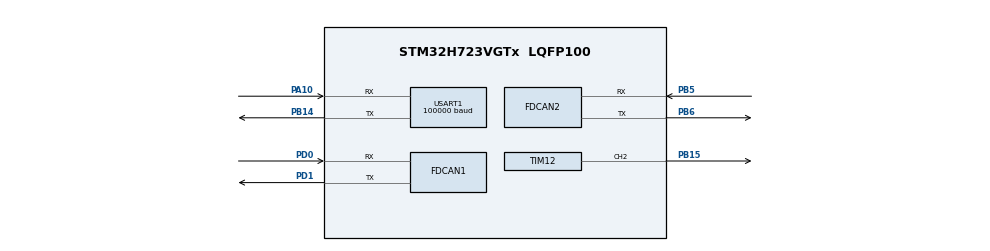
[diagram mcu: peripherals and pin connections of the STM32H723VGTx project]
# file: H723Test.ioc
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CORTEX_M7.default_mode_Activation=0
FDCAN1.AutoRetransmission=ENABLE
FDCAN1.CalculateBaudRateNominal=1000000
FDCAN1.CalculateTimeBitNominal=1000
FDCAN1.CalculateTimeQuantumNominal=12.5
FDCAN1.DataSyncJumpWidth=1
FDCAN1.DataTimeSeg1=1
FDCAN1.DataTimeSeg2=1
FDCAN1.ExtFiltersNbr=0
FDCAN1.FrameFormat=FDCAN_FRAME_CLASSIC
FDCAN1.NominalPrescaler=1
FDCAN1.NominalSyncJumpWidth=20
FDCAN1.NominalTimeSeg1=59
FDCAN1.NominalTimeSeg2=20
FDCAN1.ProtocolException=ENABLE
FDCAN1.RxBuffersNbr=0
FDCAN1.RxFifo0ElmtsNbr=10
FDCAN1.RxFifo1ElmtsNbr=0
FDCAN1.StdFiltersNbr=4
FDCAN1.TxBuffersNbr=0
FDCAN1.TxEventsNbr=0
FDCAN1.TxFifoQueueElmtsNbr=10
FDCAN2.AutoRetransmission=ENABLE
FDCAN2.CalculateBaudRateNominal=1000000
FDCAN2.CalculateTimeBitNominal=1000
FDCAN2.CalculateTimeQuantumNominal=12.5
FDCAN2.NominalPrescaler=1
FDCAN2.NominalSyncJumpWidth=20
FDCAN2.NominalTimeSeg1=59
FDCAN2.NominalTimeSeg2=20
FDCAN2.RxFifo0ElmtsNbr=10
FDCAN2.StdFiltersNbr=4
FDCAN2.TxFifoQueueElmtsNbr=10
FREERTOS.Tasks01=defaultTask,0,128,StartDefaultTask,Default,NULL,Dynamic,NULL,NULL
FREERTOS.configENABLE_FPU=1
Mcu.Family=STM32H7
Mcu.Name=STM32H723VGTx
Mcu.Package=LQFP100
NVIC.FDCAN1_IT0_IRQn=true\:5\:0\:false\:false\:true\:true\:true\:true\:true
NVIC.FDCAN2_IT0_IRQn=true\:5\:0\:false\:false\:true\:true\:true\:true\:true
NVIC.PriorityGroup=NVIC_PRIORITYGROUP_4
NVIC.TIM1_UP_IRQn=true\:15\:0\:false\:false\:true\:false\:false\:true\:true
NVIC.TimeBase=TIM1_UP_IRQn
NVIC.TimeBaseIP=TIM1
PA10.Mode=Asynchronous
PA10.Signal=USART1_RX
PA13(JTMS/SWDIO).Mode=Serial_Wire
PA13(JTMS/SWDIO).Signal=DEBUG_JTMS-SWDIO
PA14(JTCK/SWCLK).Mode=Serial_Wire
PA14(JTCK/SWCLK).Signal=DEBUG_JTCK-SWCLK
PB14.Mode=Asynchronous
PB14.Signal=USART1_TX
PB15.Signal=S_TIM12_CH2
PB5.Mode=FDCAN_Activate
PB5.Signal=FDCAN2_RX
PB6.Mode=FDCAN_Activate
PB6.Signal=FDCAN2_TX
PD0.Mode=FDCAN_Activate
PD0.Signal=FDCAN1_RX
PD1.Mode=FDCAN_Activate
PD1.Signal=FDCAN1_TX
PH0-OSC_IN.Mode=HSE-External-Oscillator
PH0-OSC_IN.Signal=RCC_OSC_IN
PH1-OSC_OUT.Mode=HSE-External-Oscillator
PH1-OSC_OUT.Signal=RCC_OSC_OUT
ProjectManager.HeapSize=0x200
ProjectManager.StackSize=0x400
ProjectManager.TargetToolchain=CMake
RCC.ADCFreq_Value=48375000
RCC.APB1Freq_Value=120000000
RCC.APB2Freq_Value=120000000
RCC.APB3Freq_Value=120000000
RCC.APB4Freq_Value=120000000
RCC.CortexFreq_Value=480000000
RCC.D1PPRE=RCC_APB3_DIV2
RCC.D2PPRE1=RCC_APB1_DIV2
RCC.D2PPRE2=RCC_APB2_DIV2
RCC.D3PPRE=RCC_APB4_DIV2
RCC.DIVM1=2
RCC.DIVN1=40
RCC.DIVP1=1
RCC.DIVQ1=6
RCC.HCLKFreq_Value=240000000
RCC.HPRE=RCC_HCLK_DIV2
RCC.HSE_VALUE=24000000
RCC.PLLFRACN=0
RCC.PLLSourceVirtual=RCC_PLLSOURCE_HSE
RCC.SYSCLKFreq_VALUE=480000000
RCC.SYSCLKSource=RCC_SYSCLKSOURCE_PLLCLK
RCC.USBFreq_Value=80000000
SH.S_TIM12_CH2.0=TIM12_CH2,PWM Generation2 CH2
STMicroelectronics.X-CUBE-ALGOBUILD.1.4.0.LibraryCcDSPOoLibraryJjDSPOoLibrary=true
TIM12.AutoReloadPreload=TIM_AUTORELOAD_PRELOAD_ENABLE
TIM12.Channel-PWM\ Generation2\ CH2=TIM_CHANNEL_2
TIM12.Period=249
TIM12.Prescaler=119
USART1.BaudRate=100000
USART1.Parity=PARITY_EVEN
USART1.StopBits=STOPBITS_2
USART1.VirtualMode-Asynchronous=VM_ASYNC
VP_FREERTOS_VS_CMSIS_V1.Mode=CMSIS_V1
VP_MEMORYMAP_VS_MEMORYMAP.Mode=CurAppReg
VP_STMicroelectronics.X-CUBE-ALGOBUILD_VS_DSPOoLibraryJjLibrary_1.4.0_1.4.0.Mode=DSPOoLibraryJjLibrary
VP_SYS_VS_tim1.Mode=TIM1
board=custom

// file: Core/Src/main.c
/* USER CODE BEGIN Header */
/**
  ******************************************************************************
  * @file           : main.c
  * @brief          : Main program body
  ******************************************************************************
  * @attention
  *
  * Copyright (c) 2026 STMicroelectronics.
  * All rights reserved.
  *
  * This software is licensed under terms that can be found in the LICENSE file
  * in the root directory of this software component.
  * If no LICENSE file comes with this software, it is provided AS-IS.
  *
  ******************************************************************************
  */
/* USER CODE END Header */
#include "main.h"
#include "cmsis_os.h"
#include "fdcan.h"
#include "memorymap.h"
#include "tim.h"
#include "usart.h"
#include "gpio.h"

/* USER CODE BEGIN Includes */
#include "bsp_fdcan.h"
/* USER CODE END Includes */

void SystemClock_Config(void);
void MX_FREERTOS_Init(void);

int main(void)
{

  /* MCU Configuration--------------------------------------------------------*/

  /* Reset of all peripherals, Initializes the Flash interface and the Systick. */
  HAL_Init();

  /* Configure the system clock */
  SystemClock_Config();

  /* Initialize all configured peripherals */
  MX_GPIO_Init();
  MX_FDCAN1_Init();
  MX_TIM12_Init();
  MX_USART1_UART_Init();
  MX_FDCAN2_Init();
  /* USER CODE BEGIN 2 */
  BSP_FDCAN_Init();

  /* USER CODE END 2 */

  /* Call init function for freertos objects (in cmsis_os2.c) */
  MX_FREERTOS_Init();

  /* Start scheduler */
  osKernelStart();

  /* We should never get here as control is now taken by the scheduler */

  /* Infinite loop */
  /* USER CODE BEGIN WHILE */
  while (1)
  {
    bsp_fdcan_djimotorcmd(1000,1000,1000,1000);
    HAL_Delay(10);
    /* USER CODE END WHILE */

  }
}

void SystemClock_Config(void)
{
  RCC_OscInitTypeDef RCC_OscInitStruct = {0};
  RCC_ClkInitTypeDef RCC_ClkInitStruct = {0};

  /** Supply configuration update enable
  */
  HAL_PWREx_ConfigSupply(PWR_LDO_SUPPLY);

  /** Configure the main internal regulator output voltage
  */
  __HAL_PWR_VOLTAGESCALING_CONFIG(PWR_REGULATOR_VOLTAGE_SCALE0);

  while(!__HAL_PWR_GET_FLAG(PWR_FLAG_VOSRDY)) {}

  /** Initializes the RCC Oscillators according to the specified parameters
  * in the RCC_OscInitTypeDef structure.
  */
  RCC_OscInitStruct.OscillatorType = RCC_OSCILLATORTYPE_HSE;
  RCC_OscInitStruct.HSEState = RCC_HSE_ON;
  RCC_OscInitStruct.PLL.PLLState = RCC_PLL_ON;
  RCC_OscInitStruct.PLL.PLLSource = RCC_PLLSOURCE_HSE;
  RCC_OscInitStruct.PLL.PLLM = 2;
  RCC_OscInitStruct.PLL.PLLN = 40;
  RCC_OscInitStruct.PLL.PLLP = 1;
  RCC_OscInitStruct.PLL.PLLQ = 6;
  RCC_OscInitStruct.PLL.PLLR = 2;
  RCC_OscInitStruct.PLL.PLLRGE = RCC_PLL1VCIRANGE_3;
  RCC_OscInitStruct.PLL.PLLVCOSEL = RCC_PLL1VCOWIDE;
  RCC_OscInitStruct.PLL.PLLFRACN = 0;
  if (HAL_RCC_OscConfig(&RCC_OscInitStruct) != HAL_OK)
  {
    Error_Handler();
  }

  /** Initializes the CPU, AHB and APB buses clocks
  */
  RCC_ClkInitStruct.ClockType = RCC_CLOCKTYPE_HCLK|RCC_CLOCKTYPE_SYSCLK
                              |RCC_CLOCKTYPE_PCLK1|RCC_CLOCKTYPE_PCLK2
                              |RCC_CLOCKTYPE_D3PCLK1|RCC_CLOCKTYPE_D1PCLK1;
  RCC_ClkInitStruct.SYSCLKSource = RCC_SYSCLKSOURCE_PLLCLK;
  RCC_ClkInitStruct.SYSCLKDivider = RCC_SYSCLK_DIV1;
  RCC_ClkInitStruct.AHBCLKDivider = RCC_HCLK_DIV2;
  RCC_ClkInitStruct.APB3CLKDivider = RCC_APB3_DIV2;
  RCC_ClkInitStruct.APB1CLKDivider = RCC_APB1_DIV2;
  RCC_ClkInitStruct.APB2CLKDivider = RCC_APB2_DIV2;
  RCC_ClkInitStruct.APB4CLKDivider = RCC_APB4_DIV2;

  if (HAL_RCC_ClockConfig(&RCC_ClkInitStruct, FLASH_LATENCY_3) != HAL_OK)
  {
    Error_Handler();
  }
}

void HAL_TIM_PeriodElapsedCallback(TIM_HandleTypeDef *htim)
{
  if (htim->Instance == TIM1)
  {
    HAL_IncTick();
  }
}

void Error_Handler(void)
{
  __disable_irq();
  while (1)
  {
  }
}
